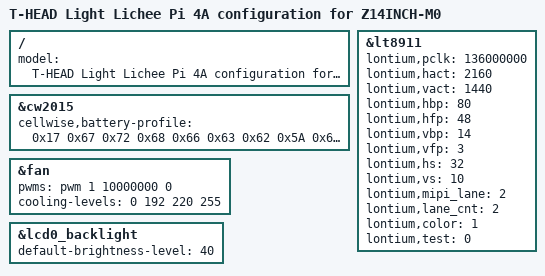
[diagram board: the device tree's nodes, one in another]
/* SPDX-License-Identifier: GPL-2.0 */
/*
 * Copyright (C) 2023 Sipeed.
 */

#include "light-lpi4a-laptop.dts"

/ {
        model = "T-HEAD Light Lichee Pi 4A configuration for Z14INCH-M0";
};

&cw2015 {
	cellwise,battery-profile = /bits/ 8 <
		0x17 0x67 0x72 0x68 0x66 0x63 0x62 0x5A
		0x64 0x61 0x4D 0x57 0x5A 0x51 0x43 0x38
		0x31 0x2A 0x24 0x22 0x29 0x31 0x3E 0x4C
		0x29 0x4D 0x0B 0x85 0x1C 0x38 0x47 0x57
		0x5D 0x5E 0x5F 0x60 0x3F 0x1A 0x6F 0x41
		0x0A 0x43 0x12 0x38 0x7B 0x95 0x9A 0x18
		0x4B 0x6F 0x9E 0xD5 0x80 0x57 0x87 0xCB
		0x2F 0x00 0x64 0xA5 0xB5 0x13 0x54 0xB9
	>;
};

&lt8911 {
	lontium,pclk = <136000000>;
	lontium,hact = <2160>;
	lontium,vact = <1440>;
	lontium,hbp = <80>;
	lontium,hfp = <48>;
	lontium,vbp = <14>;
	lontium,vfp = <3>;
	lontium,hs = <32>;
	lontium,vs = <10>;
	lontium,mipi_lane = <2>;
	lontium,lane_cnt = <2>;
	lontium,color = <1>; //Color Depth 0:6bit 1:8bit
	lontium,test = <0>;
};

&fan {
        pwms = <&pwm 1 10000000 0>;
        cooling-levels = <0 192 220 255>;
};

&lcd0_backlight {
        default-brightness-level = <40>;
};
